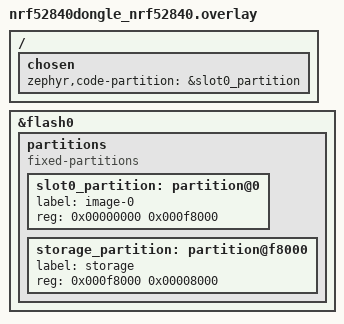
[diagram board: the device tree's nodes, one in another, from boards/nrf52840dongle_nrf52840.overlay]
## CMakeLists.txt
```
cmake_minimum_required(VERSION 3.20.0)
find_package(Zephyr REQUIRED HINTS $ENV{ZEPHYR_BASE})
project(pca10059Test)

target_sources(app PRIVATE src/main.c)
```

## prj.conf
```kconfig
CONFIG_GPIO=y
CONFIG_USE_DT_CODE_PARTITION=y
CONFIG_USB_DEVICE_STACK=n
CONFIG_SERIAL=n
CONFIG_CONSOLE=n
CONFIG_UART_CONSOLE=n
```

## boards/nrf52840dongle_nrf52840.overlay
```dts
/ {
	chosen {
		zephyr,code-partition = &slot0_partition;
	};
};

&flash0 {
	/delete-node/ partitions;

	partitions {
		compatible = "fixed-partitions";
		#address-cells = <1>;
		#size-cells = <1>;

		slot0_partition: partition@0 {
			label = "image-0";
			reg = <0x00000000 0x000f8000>;
		};
		storage_partition: partition@f8000 {
			label = "storage";
			reg = <0x000f8000 0x00008000>;
		};
	};
};
```

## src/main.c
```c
#include <zephyr/kernel.h>
#include <zephyr/drivers/gpio.h>

#define SLEEP_TIME_MS 500

static const struct gpio_dt_spec led = GPIO_DT_SPEC_GET(DT_ALIAS(led0), gpios);

int main(void)
{
	if (!gpio_is_ready_dt(&led)) {
		return -1;
	}
	gpio_pin_configure_dt(&led, GPIO_OUTPUT_INACTIVE);

	while (1) {
		gpio_pin_toggle_dt(&led);
		k_msleep(SLEEP_TIME_MS);
	}

	return 0;
}
```
